VERSION "J35_6AT"

NS_ :

BS_:

BU_: EPS PCM UNKNOWN

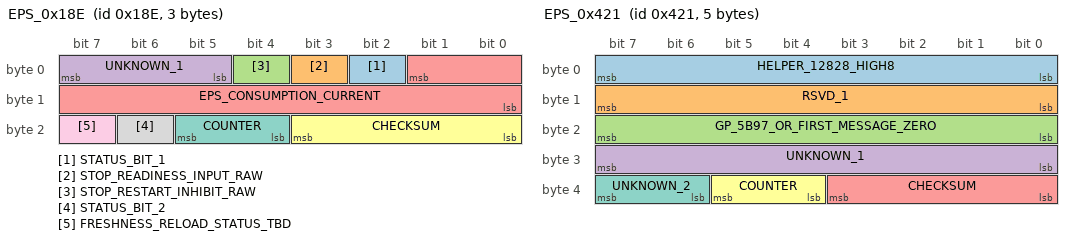
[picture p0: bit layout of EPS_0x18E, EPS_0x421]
BO_ 398 EPS_0x18E: 3 EPS
 SG_ STATUS_BIT_1 : 2|1@1+ (1,0) [0|1] ""  PCM
 SG_ STOP_READINESS_INPUT_RAW : 3|1@1+ (1,0) [0|1] ""  PCM
 SG_ STOP_RESTART_INHIBIT_RAW : 4|1@1+ (1,0) [0|1] ""  PCM
 SG_ UNKNOWN_1 : 5|3@1+ (1,0) [0|7] ""  PCM
 SG_ EPS_CONSUMPTION_CURRENT : 1|10@0+ (1,0) [0|1023] "raw"  PCM
 SG_ CHECKSUM : 16|4@1+ (1,0) [0|15] ""  PCM
 SG_ COUNTER : 20|2@1+ (1,0) [0|3] ""  PCM
 SG_ STATUS_BIT_2 : 22|1@1+ (1,0) [0|1] ""  PCM
 SG_ FRESHNESS_RELOAD_STATUS_TBD : 23|1@1+ (1,0) [0|1] ""  PCM

BO_ 1057 EPS_0x421: 5 EPS
 SG_ HELPER_12828_HIGH8 : 0|8@1+ (1,0) [0|255] ""  UNKNOWN
 SG_ RSVD_1 : 8|8@1+ (1,0) [0|255] ""  UNKNOWN
 SG_ GP_5B97_OR_FIRST_MESSAGE_ZERO : 16|8@1+ (1,0) [0|255] ""  UNKNOWN
 SG_ UNKNOWN_1 : 24|8@1+ (1,0) [0|255] ""  UNKNOWN
 SG_ CHECKSUM : 32|4@1+ (1,0) [0|15] ""  UNKNOWN
 SG_ COUNTER : 36|2@1+ (1,0) [0|3] ""  UNKNOWN
 SG_ UNKNOWN_2 : 38|2@1+ (1,0) [0|3] ""  UNKNOWN
